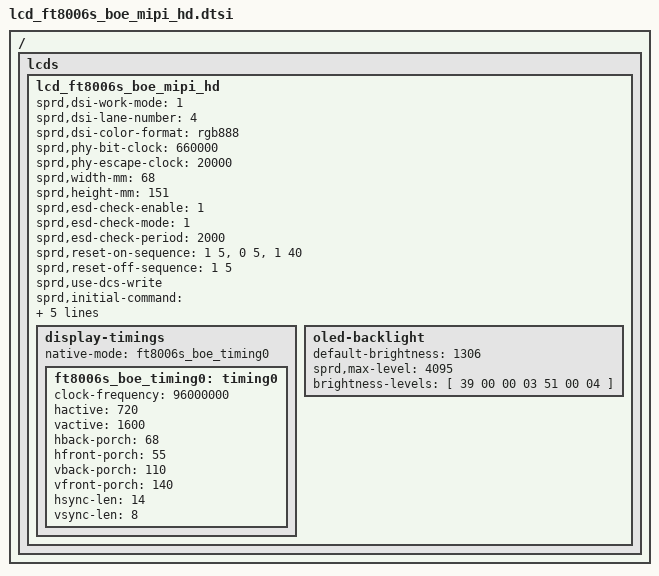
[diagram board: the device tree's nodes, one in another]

/*
 * R61350 Truly LCD config dtsi file for spreadtrum
 *
 * Copyright (C) 2018, Spreadtrum Communications Inc.
 *
 * SPDX-License-Identifier: (GPL-2.0+ OR MIT)
 */

/ {
	fragment {
		target-path = "/";
		__overlay__ {
			lcds {
				lcd_ft8006s_boe_mipi_hd: lcd_ft8006s_boe_mipi_hd {

					sprd,dsi-work-mode = <1>; /* video burst mode*/
					sprd,dsi-lane-number = <4>;
					sprd,dsi-color-format = "rgb888";

					sprd,phy-bit-clock = <660000>;	/* kbps */
					sprd,phy-escape-clock = <20000>;/* kHz */

					sprd,width-mm = <68>;
					sprd,height-mm = <151>;

					sprd,esd-check-enable = <1>;
					sprd,esd-check-mode = <1>;
					sprd,esd-check-period = <2000>;
					/* sprd,esd-check-register = <0x0A>; */
					/* sprd,esd-check-value = <0x9C>; */

					sprd,reset-on-sequence = <1 5>, <0 5>, <1 40>;
					sprd,reset-off-sequence = <1 5>;

 
					sprd,use-dcs-write;
					sprd,initial-command = [
					39 00 00 02 41 5A 
					39 00 00 03 41 5A 24 
					39 00 00 02 90 5A 
					39 00 00 03 41 5A 08 
					39 00 00 04 80 C8 2C 01 
					39 00 00 03 41 5A 09 
					39 00 00 11 80 5A 51 B5 2A 6C E5 4A 01 40 62 0F 82 20 08 F0 B7 
					39 00 00 11 90 00 24 42 0A E3 91 A4 F0 69 43 55 20 37 C1 26 00 
					39 00 00 11 A0 51 55 55 00 A0 4C 06 11 0D 60 00 FF FF 03 A5 E6 
					39 00 00 11 B0 08 3A 12 64 0B 00 00 11 00 60 00 FF FF 03 FF 34 
					39 00 00 09 C0 0C FF 18 9F 0F 00 08 00 
					39 00 00 03 41 5A 0A 
					39 00 00 11 80 FF 83 07 03 00 19 2B 40 55 69 71 A6 9D D6 62 2E 
					39 00 00 11 90 73 4A 47 37 27 1B 0E 0B 00 19 2B 40 55 69 71 A6 
					39 00 00 0E A0 9D D6 62 2E 73 4A 47 37 27 1B 0E 0B 00 
					39 00 00 03 41 5A 0B 
					39 00 00 11 80 00 00 20 44 08 00 60 47 00 00 10 22 04 00 B0 23 
					39 00 00 03 90 15 00 
					39 00 00 03 41 5A 0C 
					39 00 00 11 80 FA 68 68 01 32 37 D0 07 00 60 15 00 50 15 56 51 
					39 00 00 11 90 15 55 61 15 00 60 15 00 50 15 56 51 15 55 61 95 
					39 00 00 11 A0 AB 18 00 05 00 05 00 05 80 4C 29 84 52 01 09 00 
					39 00 00 03 B0 00 00 
					39 00 00 03 41 5A 0D 
					39 00 00 08 80 F0 B1 71 EF 4B C0 80 
					39 00 00 03 41 5A 0E 
					39 00 00 09 80 FF 01 55 55 32 88 88 1C 
					39 00 00 03 41 5A 0F 
					39 00 00 11 80 BD 07 70 60 11 D0 63 08 52 51 88 49 03 52 4C 4C 
					39 00 00 11 90 68 68 68 4C 4C 7C 14 00 20 06 C2 00 04 06 0C 00 
					39 00 00 05 A0 00 92 00 00 
					39 00 00 03 41 5A 10 
					39 00 00 11 80 00 00 03 E7 1F 17 10 48 80 AA D0 18 30 88 41 8A 
					39 00 00 10 90 39 28 A9 C5 9A 7B F0 07 7E E0 07 7E 20 10 00 
					39 00 00 03 41 5A 11 
					39 00 00 11 80 46 77 03 40 CA F3 FF A3 20 08 C4 06 A1 D8 24 18 
					39 00 00 11 90 30 C6 66 C1 80 51 15 CB E5 D2 68 6C 36 1D 04 C8 
					39 00 00 11 A0 B0 D9 88 60 B0 81 40 1A 1B 48 63 03 B9 00 1C 80 
					39 00 00 11 B0 50 30 00 E0 E1 01 00 28 0E 06 43 55 55 55 55 55 
					39 00 00 11 C0 95 88 88 88 88 88 C8 08 84 C6 E3 81 00 20 00 21 
					39 00 00 11 D0 42 88 20 09 10 00 40 80 24 31 04 41 26 49 92 24 
					39 00 00 11 E0 49 00 20 49 92 04 00 00 00 00 92 04 00 85 11 0C 
					39 00 00 10 F0 00 00 40 00 00 00 00 5E 4A 01 78 00 08 00 00 
					39 00 00 03 41 5A 12 
					39 00 00 11 80 00 00 00 00 00 02 03 00 00 00 00 02 03 01 41 37 
					39 00 00 11 90 F1 E7 00 00 00 00 00 00 00 00 00 00 00 2D 23 05 
					39 00 00 08 A0 FB 08 2D 23 05 FB 0C 
					39 00 00 03 41 5A 13 
					39 00 00 11 80 FD 0F 00 0C 00 00 00 00 01 08 01 1C 44 0C CE E7 
					39 00 00 0F 90 62 0E 24 98 AC 21 01 00 D0 93 24 49 06 20 
					39 00 00 03 41 5A 14 
					39 00 00 11 80 C1 02 41 36 E1 EF F7 FB FD 7E 00 00 00 90 C5 81 
					39 00 00 11 90 40 20 20 06 04 02 01 1B E9 F1 08 00 00 99 0C 04 
					39 00 00 11 A0 00 C8 64 60 00 00 00 00 00 20 8B A8 55 26 03 20 
					39 00 00 11 B0 A2 49 99 0C 00 00 00 00 00 64 32 26 2B 00 40 A1 
					39 00 00 11 C0 50 38 23 02 3C 80 51 1C E7 43 80 07 30 8A E3 6C 
					39 00 00 11 D0 08 F0 00 46 71 9C 0B 01 1E C0 28 0E 77 E1 7F CF 
					39 00 00 11 E0 19 C5 E1 26 FC EF 19 A3 38 DC 83 FF 3D 63 14 87 
					39 00 00 11 F0 5B F0 BF 67 8C E2 18 01 BF DF 08 00 00 00 00 00 
					39 00 00 03 41 5A 15 
					39 00 00 11 80 00 00 00 00 00 00 00 00 00 00 00 00 8E D9 E0 F7 
					39 00 00 11 90 53 00 20 CB 44 2C 93 01 00 00 5C 31 6A F1 41 0A 
					39 00 00 11 A0 78 00 00 00 00 00 00 00 00 00 00 00 00 00 00 90 
					39 00 00 11 B0 D5 12 53 28 4E C4 32 19 12 00 F0 00 88 96 24 21 
					39 00 00 11 C0 EC 03 41 CA 34 09 C0 5A D7 B6 6D DB B6 6D 49 52 
					39 00 00 11 D0 FA 30 10 A4 4C 53 30 AC 75 6D DB B6 6D DB 96 24 
					39 00 00 11 E0 25 EC 03 41 CA 34 0D C1 5A DB B6 6D DB B6 6D 49 
					39 00 00 11 F0 12 FA 30 10 A4 4C 13 20 AC B5 6D DB B6 6D 5B C0 
					39 00 00 03 41 5A 16 
					39 00 00 11 80 C3 43 41 01 00 00 00 00 00 00 00 00 00 00 00 00 
					39 00 00 07 90 00 00 00 00 50 21 
					39 00 00 03 41 5A 18 
					39 00 00 11 80 EF BD F7 DE 7B EF BD 07 08 08 0A 0C 0C 0C 0C 0C 
					39 00 00 11 90 0C 0C 0C 5C 09 A8 AA AA AA AA AA AA AA AA AA 5A 
					39 00 00 11 A0 59 59 59 59 59 59 59 59 59 59 59 09 04 FF 00 80 
					39 00 00 10 B0 80 00 04 20 00 01 08 40 00 02 10 80 00 04 00 
					39 00 00 03 41 5A 19 
					39 00 00 11 80 91 8D 8A 8A 87 87 85 83 83 82 81 80 FF DF 4C AA 
					39 00 00 11 90 F7 EF 28 D3 AF 8D 0D FF AF B5 71 0E 6C 4A 69 08 
					39 00 00 05 A0 00 00 08 00 
					39 00 00 03 41 5A 1A 
					39 00 00 11 80 00 04 08 0C 00 10 14 18 1C 00 20 28 30 38 00 40 
					39 00 00 11 90 48 50 58 00 60 67 6F 77 FC 80 88 90 98 00 A0 A8 
					39 00 00 11 A0 B0 B8 40 C0 C8 D0 D8 55 E0 E8 F0 F8 15 FC FE FF 
					39 00 00 11 B0 00 00 04 08 0C 00 10 14 18 1C 00 20 28 30 38 00 
					39 00 00 11 C0 40 48 50 58 54 60 68 70 78 55 80 88 90 98 55 A0 
					39 00 00 11 D0 A8 B0 B8 55 C0 C8 D0 D8 01 E0 E8 F0 F7 C0 FB FD 
					39 00 00 11 E0 FE 3F 00 03 07 0B BC 0F 13 17 1B 16 1F 26 2E 36 
					39 00 00 11 F0 6C 3D 45 4D 55 1B 5C 64 6C 74 1B 7B 83 8B 93 AF 
					39 00 00 03 41 5A 1B 
					39 00 00 11 80 9B A3 AB B3 55 BB C3 CB D3 E9 DC E4 ED F5 C8 FA 
					39 00 00 05 90 FC FE 0D 00 
					39 00 00 03 41 5A 20 
					39 00 00 08 80 7A 00 00 00 00 00 00 
					39 00 00 03 41 5A 22 
					39 00 00 0E 80 2D D3 00 55 55 01 55 55 01 55 55 9F 00 
					39 00 00 03 41 5A 23 
					39 00 00 11 80 01 05 00 05 00 00 00 00 00 00 00 00 00 00 00 01 
					39 00 00 0D 90 FF 0F 00 00 00 03 00 00 00 FF 07 35 
					39 00 00 03 41 5A 24 
					39 00 00 11 80 00 03 00 FF FF 20 00 00 00 00 00 00 00 00 DA 5A 
					39 00 00 11 90 5A 5A 5A 55 00 00 00 00 00 00 00 00 00 00 00 00 
					39 00 00 02 42 24 
					39 00 00 02 90 00 
					39 00 00 03 41 5A 2F 
					39 00 00 03 90 0F 0A
					39 00 00 02 94 01
					39 00 00 02 19 01 
					39 00 00 02 4C 03
					05 78 00 01 11 
					39 00 00 03 51 00 00
					39 00 00 02 53 24 
					39 0A 00 02 55 00
					05 00 00 01 29
					
						];

					sprd,sleep-in-command = [
					  15 5A 00 01 28
					  15 5F 00 01 10
					  29 00 00 02 17 5A
					  29 14 00 02 18 5A
					  ];

					sprd,sleep-out-command = [
					  15 78 00 01 11
					  15 14 00 01 29   
					  ];                 

					display-timings {
						native-mode = <&ft8006s_boe_timing0>;
						ft8006s_boe_timing0: timing0 {
							clock-frequency = <96000000>;
							hactive = <720>;
							vactive = <1600>;
							hback-porch = <68>;
							hfront-porch = <55>;
							vback-porch = <110>;
							vfront-porch = <140>;
							hsync-len = <14>;
							vsync-len = <8>;
						};
					};

					
					oled-backlight {			
						default-brightness = <1306>;	
						sprd,max-level = <4095>;
						brightness-levels = [				
						39 00 00 03 51 00 04	
						];
					};
				};
			};
		};
	};
};
